# EFM32GG980F1024 register map
File version: 5.8.2
CPU: CM3 r2p1, little endian, MPU, no FPU, 3 interrupt priority bits
Registers are 32-bit, read-write, reset 0x0 unless marked. A register's access mark holds for its fields unless they carry their own. Offsets are from the block's base; [hi:lo] are bit positions; {n}, {i} and the like mark numbered series.

## CMU
Base 0x400C8000
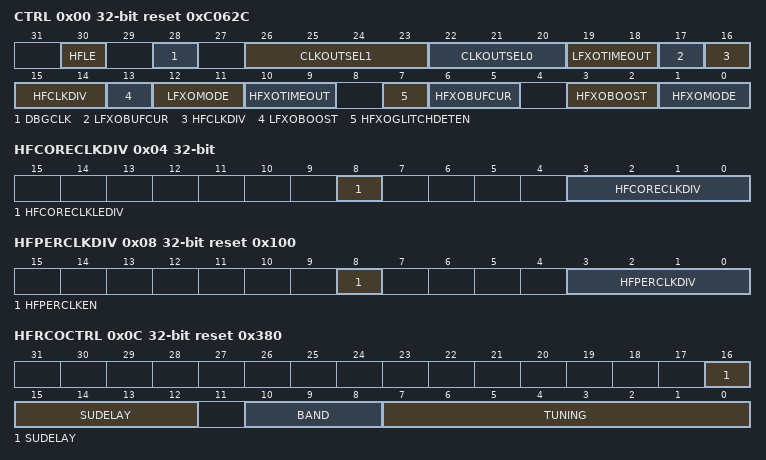
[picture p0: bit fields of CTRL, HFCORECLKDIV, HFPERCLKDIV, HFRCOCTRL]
0x00 CTRL reset 0xC062C — CMU Control Register
  [30] HFLE — High-Frequency LE Interface
  [28] DBGCLK — Debug Clock
  [26:23] CLKOUTSEL1 — Clock Output Select 1
    0=LFRCO (LFRCO (directly from oscillator).); 1=LFXO (LFXO (directly from oscillator).); 2=HFCLK (HFCLK (undivided).); 3=LFXOQ (LFXO (qualified).); 4=HFXOQ (HFXO (qualified).); 5=LFRCOQ (LFRCO (qualified).); 6=HFRCOQ (HFRCO (qualified).); 7=AUXHFRCOQ (AUXHFRCO (qualified).)
  [22:20] CLKOUTSEL0 — Clock Output Select 0
    0=HFRCO (HFRCO (directly from oscillator).); 1=HFXO (HFXO (directly from oscillator).); 2=HFCLK2; 3=HFCLK4; 4=HFCLK8; 5=HFCLK16; 6=ULFRCO (ULFRCO (directly from oscillator).); 7=AUXHFRCO (AUXHFRCO (directly from oscillator).)
  [19:18] LFXOTIMEOUT
    0=8CYCLES (Timeout period of 8 cycles.); 1=1KCYCLES (Timeout period of 1024 cycles.); 2=16KCYCLES (Timeout period of 16384 cycles.); 3=32KCYCLES (Timeout period of 32768 cycles.)
  [17] LFXOBUFCUR — LFXO Boost Buffer Current
  [16:14] HFCLKDIV — HFCLK Division
  [13] LFXOBOOST — LFXO Start-up Boost Current
  [12:11] LFXOMODE
    0=XTAL (32.768 kHz crystal oscillator.); 1=BUFEXTCLK (An AC coupled buffer is coupled in series with LFXTAL_N pin, suitable for external sinus wave (32.768 kHz).); 2=DIGEXTCLK (Digital external clock on LFXTAL_N pin. Oscillator is effectively bypassed.)
  [10:9] HFXOTIMEOUT
    0=8CYCLES (Timeout period of 8 cycles.); 1=256CYCLES (Timeout period of 256 cycles.); 2=1KCYCLES (Timeout period of 1024 cycles.); 3=16KCYCLES (Timeout period of 16384 cycles.)
  [7] HFXOGLITCHDETEN — HFXO Glitch Detector Enable
  [6:5] HFXOBUFCUR — HFXO Boost Buffer Current
    1=BOOSTUPTO32MHZ (Boost Buffer Current level when HFXO is below or equal to 32 MHz.); 3=BOOSTABOVE32MHZ (Boost Buffer Current Level when HFXO is above 32 MHz.)
  [3:2] HFXOBOOST — HFXO Start-up Boost Current
    0=50PCENT; 1=70PCENT; 2=80PCENT; 3=100PCENT (100 % (default).)
  [1:0] HFXOMODE
    0=XTAL (4-48 MHz crystal oscillator.); 1=BUFEXTCLK (An AC coupled buffer is coupled in series with HFXTAL_N, suitable for external sine wave (4-48 MHz). The sine wave should have a minimum of 200 mV peak to peak.); 2=DIGEXTCLK (Digital external clock on HFXTAL_N pin. Oscillator is effectively bypassed.)
0x04 HFCORECLKDIV — High Frequency Core Clock Division Register
  [8] HFCORECLKLEDIV — Additional Division Factor For HFCORECLKLE
  [3:0] HFCORECLKDIV — HFCORECLK Divider
    0=HFCLK (HFCORECLK = HFCLK.); 1=HFCLK2 (HFCORECLK = HFCLK/2.); 2=HFCLK4 (HFCORECLK = HFCLK/4.); 3=HFCLK8 (HFCORECLK = HFCLK/8.); 4=HFCLK16 (HFCORECLK = HFCLK/16.); 5=HFCLK32 (HFCORECLK = HFCLK/32.); 6=HFCLK64 (HFCORECLK = HFCLK/64.); 7=HFCLK128 (HFCORECLK = HFCLK/128.); 8=HFCLK256 (HFCORECLK = HFCLK/256.); 9=HFCLK512 (HFCORECLK = HFCLK/512.)
0x08 HFPERCLKDIV reset 0x100 — High Frequency Peripheral Clock Division Register
  [8] HFPERCLKEN — HFPERCLK Enable
  [3:0] HFPERCLKDIV — HFPERCLK Divider
    0=HFCLK (HFPERCLK = HFCLK.); 1=HFCLK2 (HFPERCLK = HFCLK/2.); 2=HFCLK4 (HFPERCLK = HFCLK/4.); 3=HFCLK8 (HFPERCLK = HFCLK/8.); 4=HFCLK16 (HFPERCLK = HFCLK/16.); 5=HFCLK32 (HFPERCLK = HFCLK/32.); 6=HFCLK64 (HFPERCLK = HFCLK/64.); 7=HFCLK128 (HFPERCLK = HFCLK/128.); 8=HFCLK256 (HFPERCLK = HFCLK/256.); 9=HFCLK512 (HFPERCLK = HFCLK/512.)
0x0C HFRCOCTRL reset 0x380 — HFRCO Control Register
  [16:12] SUDELAY — HFRCO Start-up Delay
  [10:8] BAND — HFRCO Band Select
    0=1MHZ (1 MHz band. NOTE: Also set the TUNING value (bits 7:0) when changing band.); 1=7MHZ (7 MHz band. NOTE: Also set the TUNING value (bits 7:0) when changing band.); 2=11MHZ (11 MHz band. NOTE: Also set the TUNING value (bits 7:0) when changing band.); 3=14MHZ (14 MHz band. NOTE: Also set the TUNING value (bits 7:0) when changing band.); 4=21MHZ (21 MHz band. NOTE: Also set the TUNING value (bits 7:0) when changing band.); 5=28MHZ (28 MHz band. NOTE: Also set the TUNING value (bits 7:0) when changing band.)
  [7:0] TUNING — HFRCO Tuning Value
0x10 LFRCOCTRL reset 0x40 — LFRCO Control Register
  [6:0] TUNING — LFRCO Tuning Value
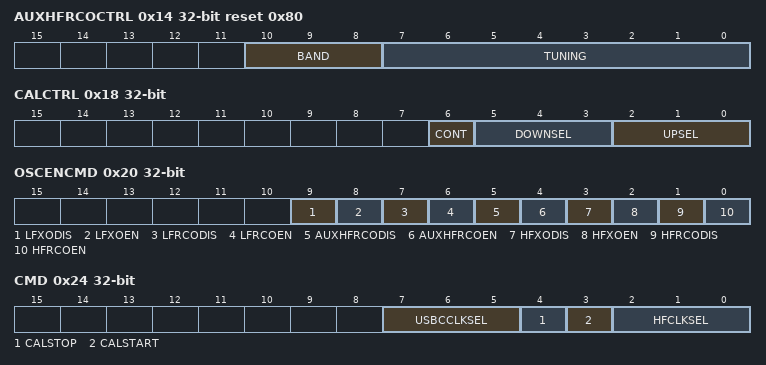
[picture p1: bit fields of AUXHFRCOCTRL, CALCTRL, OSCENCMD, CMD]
0x14 AUXHFRCOCTRL reset 0x80 — AUXHFRCO Control Register
  [10:8] BAND — AUXHFRCO Band Select
    0=14MHZ (14 MHz band. NOTE: Also set the TUNING value (bits 7:0) when changing band.); 1=11MHZ (11 MHz band. NOTE: Also set the TUNING value (bits 7:0) when changing band.); 2=7MHZ (7 MHz band. NOTE: Also set the TUNING value (bits 7:0) when changing band.); 3=1MHZ (1 MHz band. NOTE: Also set the TUNING value (bits 7:0) when changing band.); 6=28MHZ (28 MHz band. NOTE: Also set the TUNING value (bits 7:0) when changing band.); 7=21MHZ (21 MHz band. NOTE: Also set the TUNING value (bits 7:0) when changing band.)
  [7:0] TUNING — AUXHFRCO Tuning Value
0x18 CALCTRL — Calibration Control Register
  [6] CONT — Continuous Calibration
  [5:3] DOWNSEL — Calibration Down-counter Select
    0=HFCLK (Select HFCLK for down-counter.); 1=HFXO (Select HFXO for down-counter.); 2=LFXO (Select LFXO for down-counter.); 3=HFRCO (Select HFRCO for down-counter.); 4=LFRCO (Select LFRCO for down-counter.); 5=AUXHFRCO (Select AUXHFRCO for down-counter.)
  [2:0] UPSEL — Calibration Up-counter Select
    0=HFXO (Select HFXO as up-counter.); 1=LFXO (Select LFXO as up-counter.); 2=HFRCO (Select HFRCO as up-counter.); 3=LFRCO (Select LFRCO as up-counter.); 4=AUXHFRCO (Select AUXHFRCO as up-counter.)
0x1C CALCNT — Calibration Counter Register
  [19:0] CALCNT — Calibration Counter
0x20 OSCENCMD wo — Oscillator Enable/Disable Command Register
  [9] LFXODIS — LFXO Disable
  [8] LFXOEN — LFXO Enable
  [7] LFRCODIS — LFRCO Disable
  [6] LFRCOEN — LFRCO Enable
  [5] AUXHFRCODIS — AUXHFRCO Disable
  [4] AUXHFRCOEN — AUXHFRCO Enable
  [3] HFXODIS — HFXO Disable
  [2] HFXOEN — HFXO Enable
  [1] HFRCODIS — HFRCO Disable
  [0] HFRCOEN — HFRCO Enable
0x24 CMD wo — Command Register
  [7:5] USBCCLKSEL — USB Core Clock Select
    1=HFCLKNODIV (Select HFCLK (undivided) as HFCORECLKUSBC.); 2=LFXO (Select LFXO as HFCORECLKUSBC.); 3=LFRCO (Select LFRCO as HFCORECLKUSBC.)
  [4] CALSTOP — Calibration Stop
  [3] CALSTART — Calibration Start
  [2:0] HFCLKSEL — HFCLK Select
    1=HFRCO (Select HFRCO as HFCLK.); 2=HFXO (Select HFXO as HFCLK.); 3=LFRCO (Select LFRCO as HFCLK.); 4=LFXO (Select LFXO as HFCLK.)
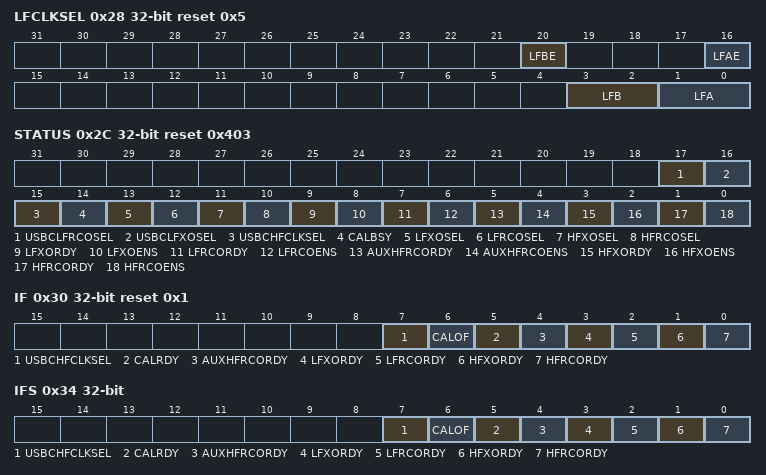
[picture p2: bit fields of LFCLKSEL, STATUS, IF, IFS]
0x28 LFCLKSEL reset 0x5 — Low Frequency Clock Select Register
  [20] LFBE — Clock Select for LFB Extended
  [16] LFAE — Clock Select for LFA Extended
  [3:2] LFB — Clock Select for LFB
    0=DISABLED (LFBCLK is disabled); 1=LFRCO (LFRCO selected as LFBCLK); 2=LFXO (LFXO selected as LFBCLK); 3=HFCORECLKLEDIV2 (HFCORECLKLE divided by two or four is selected as LFACLK. The division factor is determined by CMU_CTRL_HFLE and CMU_HFCORECLKDIV_HFCORECLKLEDIV.)
  [1:0] LFA — Clock Select for LFA
    0=DISABLED (LFACLK is disabled); 1=LFRCO (LFRCO selected as LFACLK); 2=LFXO (LFXO selected as LFACLK); 3=HFCORECLKLEDIV2 (HFCORECLKLE divided by two or four is selected as LFACLK. The division factor is determined by CMU_CTRL_HFLE and CMU_HFCORECLKDIV_HFCORECLKLEDIV.)
0x2C STATUS ro reset 0x403
  [17] USBCLFRCOSEL — USBC LFRCO Selected
  [16] USBCLFXOSEL — USBC LFXO Selected
  [15] USBCHFCLKSEL — USBC HFCLK Selected
  [14] CALBSY — Calibration Busy
  [13] LFXOSEL — LFXO Selected
  [12] LFRCOSEL — LFRCO Selected
  [11] HFXOSEL — HFXO Selected
  [10] HFRCOSEL — HFRCO Selected
  [9] LFXORDY — LFXO Ready
  [8] LFXOENS — LFXO Enable Status
  [7] LFRCORDY — LFRCO Ready
  [6] LFRCOENS — LFRCO Enable Status
  [5] AUXHFRCORDY — AUXHFRCO Ready
  [4] AUXHFRCOENS — AUXHFRCO Enable Status
  [3] HFXORDY — HFXO Ready
  [2] HFXOENS — HFXO Enable Status
  [1] HFRCORDY — HFRCO Ready
  [0] HFRCOENS — HFRCO Enable Status
0x30 IF ro reset 0x1 — Interrupt Flag Register
  [7] USBCHFCLKSEL — USBC HFCLK Selected Interrupt Flag
  [6] CALOF — Calibration Overflow Interrupt Flag
  [5] CALRDY — Calibration Ready Interrupt Flag
  [4] AUXHFRCORDY — AUXHFRCO Ready Interrupt Flag
  [3] LFXORDY — LFXO Ready Interrupt Flag
  [2] LFRCORDY — LFRCO Ready Interrupt Flag
  [1] HFXORDY — HFXO Ready Interrupt Flag
  [0] HFRCORDY — HFRCO Ready Interrupt Flag
0x34 IFS wo — Interrupt Flag Set Register
  [7] USBCHFCLKSEL — USBC HFCLK Selected Interrupt Flag Set
  [6] CALOF — Calibration Overflow Interrupt Flag Set
  [5] CALRDY — Calibration Ready Interrupt Flag Set
  [4] AUXHFRCORDY — AUXHFRCO Ready Interrupt Flag Set
  [3] LFXORDY — LFXO Ready Interrupt Flag Set
  [2] LFRCORDY — LFRCO Ready Interrupt Flag Set
  [1] HFXORDY — HFXO Ready Interrupt Flag Set
  [0] HFRCORDY — HFRCO Ready Interrupt Flag Set
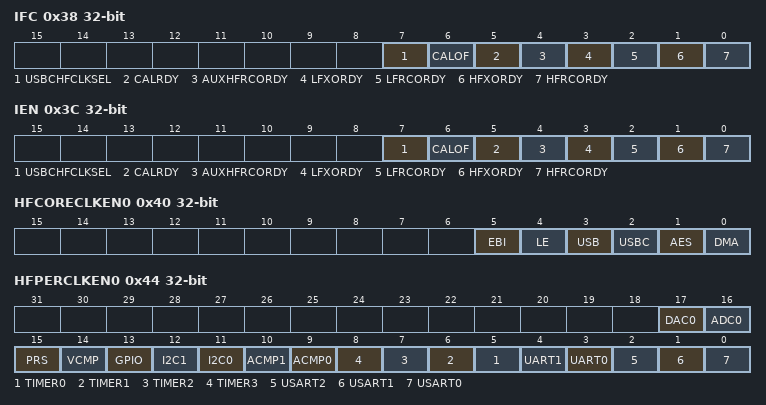
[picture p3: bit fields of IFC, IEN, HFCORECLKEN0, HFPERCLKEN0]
0x38 IFC wo — Interrupt Flag Clear Register
  [7] USBCHFCLKSEL — USBC HFCLK Selected Interrupt Flag Clear
  [6] CALOF — Calibration Overflow Interrupt Flag Clear
  [5] CALRDY — Calibration Ready Interrupt Flag Clear
  [4] AUXHFRCORDY — AUXHFRCO Ready Interrupt Flag Clear
  [3] LFXORDY — LFXO Ready Interrupt Flag Clear
  [2] LFRCORDY — LFRCO Ready Interrupt Flag Clear
  [1] HFXORDY — HFXO Ready Interrupt Flag Clear
  [0] HFRCORDY — HFRCO Ready Interrupt Flag Clear
0x3C IEN — Interrupt Enable Register
  [7] USBCHFCLKSEL — USBC HFCLK Selected Interrupt Enable
  [6] CALOF — Calibration Overflow Interrupt Enable
  [5] CALRDY — Calibration Ready Interrupt Enable
  [4] AUXHFRCORDY — AUXHFRCO Ready Interrupt Enable
  [3] LFXORDY — LFXO Ready Interrupt Enable
  [2] LFRCORDY — LFRCO Ready Interrupt Enable
  [1] HFXORDY — HFXO Ready Interrupt Enable
  [0] HFRCORDY — HFRCO Ready Interrupt Enable
0x40 HFCORECLKEN0 — High Frequency Core Clock Enable Register 0
  [5] EBI — External Bus Interface Clock Enable
  [4] LE — Low Energy Peripheral Interface Clock Enable
  [3] USB — Universal Serial Bus Interface Clock Enable
  [2] USBC — Universal Serial Bus Interface Core Clock Enable
  [1] AES — Advanced Encryption Standard Accelerator Clock Enable
  [0] DMA — Direct Memory Access Controller Clock Enable
0x44 HFPERCLKEN0 — High Frequency Peripheral Clock Enable Register 0
  [17] DAC0 — Digital to Analog Converter 0 Clock Enable
  [16] ADC0 — Analog to Digital Converter 0 Clock Enable
  [15] PRS — Peripheral Reflex System Clock Enable
  [14] VCMP — Voltage Comparator Clock Enable
  [13] GPIO — General purpose Input/Output Clock Enable
  [12] I2C1 — I2C 1 Clock Enable
  [11] I2C0 — I2C 0 Clock Enable
  [10] ACMP1 — Analog Comparator 1 Clock Enable
  [9] ACMP0 — Analog Comparator 0 Clock Enable
  [n+5] TIMER{n} (n=0..3) — Timer {n} Clock Enable
  [4] UART1 — Universal Asynchronous Receiver/Transmitter 1 Clock Enable
  [3] UART0 — Universal Asynchronous Receiver/Transmitter 0 Clock Enable
  [2] USART2 — Universal Synchronous/Asynchronous Receiver/Transmitter 2 Clock Enable
  [1] USART1 — Universal Synchronous/Asynchronous Receiver/Transmitter 1 Clock Enable
  [0] USART0 — Universal Synchronous/Asynchronous Receiver/Transmitter 0 Clock Enable
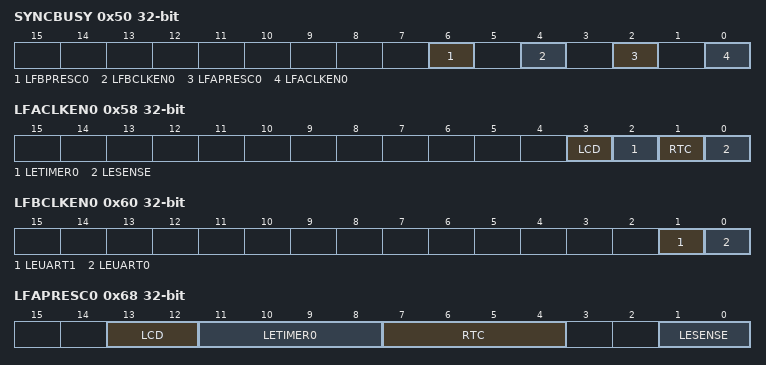
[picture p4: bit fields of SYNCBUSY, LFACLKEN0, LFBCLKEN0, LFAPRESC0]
0x50 SYNCBUSY ro — Synchronization Busy Register
  [6] LFBPRESC0 — Low Frequency B Prescaler 0 Busy
  [4] LFBCLKEN0 — Low Frequency B Clock Enable 0 Busy
  [2] LFAPRESC0 — Low Frequency A Prescaler 0 Busy
  [0] LFACLKEN0 — Low Frequency A Clock Enable 0 Busy
0x54 FREEZE
  [0] REGFREEZE — Register Update Freeze
0x58 LFACLKEN0 — Low Frequency A Clock Enable Register 0 (Async Reg)
  [3] LCD — Liquid Crystal Display Controller Clock Enable
  [2] LETIMER0 — Low Energy Timer 0 Clock Enable
  [1] RTC — Real-Time Counter Clock Enable
  [0] LESENSE — Low Energy Sensor Interface Clock Enable
0x60 LFBCLKEN0 — Low Frequency B Clock Enable Register 0 (Async Reg)
  [1] LEUART1 — Low Energy UART 1 Clock Enable
  [0] LEUART0 — Low Energy UART 0 Clock Enable
0x68 LFAPRESC0 — Low Frequency A Prescaler Register 0 (Async Reg)
  [13:12] LCD — Liquid Crystal Display Controller Prescaler
    0=DIV16 (LFACLKLCD = LFACLK/16); 1=DIV32 (LFACLKLCD = LFACLK/32); 2=DIV64 (LFACLKLCD = LFACLK/64); 3=DIV128 (LFACLKLCD = LFACLK/128)
  [11:8] LETIMER0 — Low Energy Timer 0 Prescaler
    0=DIV1 (LFACLKLETIMER0 = LFACLK); 1=DIV2 (LFACLKLETIMER0 = LFACLK/2); 2=DIV4 (LFACLKLETIMER0 = LFACLK/4); 3=DIV8 (LFACLKLETIMER0 = LFACLK/8); 4=DIV16 (LFACLKLETIMER0 = LFACLK/16); 5=DIV32 (LFACLKLETIMER0 = LFACLK/32); 6=DIV64 (LFACLKLETIMER0 = LFACLK/64); 7=DIV128 (LFACLKLETIMER0 = LFACLK/128); 8=DIV256 (LFACLKLETIMER0 = LFACLK/256); 9=DIV512 (LFACLKLETIMER0 = LFACLK/512); 10=DIV1024 (LFACLKLETIMER0 = LFACLK/1024); 11=DIV2048 (LFACLKLETIMER0 = LFACLK/2048); 12=DIV4096 (LFACLKLETIMER0 = LFACLK/4096); 13=DIV8192 (LFACLKLETIMER0 = LFACLK/8192); 14=DIV16384 (LFACLKLETIMER0 = LFACLK/16384); 15=DIV32768 (LFACLKLETIMER0 = LFACLK/32768)
  [7:4] RTC — Real-Time Counter Prescaler
    0=DIV1 (LFACLKRTC = LFACLK); 1=DIV2 (LFACLKRTC = LFACLK/2); 2=DIV4 (LFACLKRTC = LFACLK/4); 3=DIV8 (LFACLKRTC = LFACLK/8); 4=DIV16 (LFACLKRTC = LFACLK/16); 5=DIV32 (LFACLKRTC = LFACLK/32); 6=DIV64 (LFACLKRTC = LFACLK/64); 7=DIV128 (LFACLKRTC = LFACLK/128); 8=DIV256 (LFACLKRTC = LFACLK/256); 9=DIV512 (LFACLKRTC = LFACLK/512); 10=DIV1024 (LFACLKRTC = LFACLK/1024); 11=DIV2048 (LFACLKRTC = LFACLK/2048); 12=DIV4096 (LFACLKRTC = LFACLK/4096); 13=DIV8192 (LFACLKRTC = LFACLK/8192); 14=DIV16384 (LFACLKRTC = LFACLK/16384); 15=DIV32768 (LFACLKRTC = LFACLK/32768)
  [1:0] LESENSE — Low Energy Sensor Interface Prescaler
    0=DIV1 (LFACLKLESENSE = LFACLK); 1=DIV2 (LFACLKLESENSE = LFACLK/2); 2=DIV4 (LFACLKLESENSE = LFACLK/4); 3=DIV8 (LFACLKLESENSE = LFACLK/8)
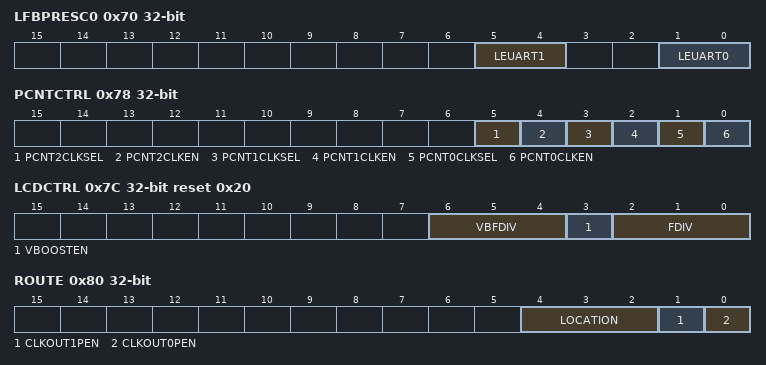
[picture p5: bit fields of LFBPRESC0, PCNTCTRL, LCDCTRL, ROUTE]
0x70 LFBPRESC0 — Low Frequency B Prescaler Register 0 (Async Reg)
  [5:4] LEUART1 — Low Energy UART 1 Prescaler
    0=DIV1 (LFBCLKLEUART1 = LFBCLK); 1=DIV2 (LFBCLKLEUART1 = LFBCLK/2); 2=DIV4 (LFBCLKLEUART1 = LFBCLK/4); 3=DIV8 (LFBCLKLEUART1 = LFBCLK/8)
  [1:0] LEUART0 — Low Energy UART 0 Prescaler
    0=DIV1 (LFBCLKLEUART0 = LFBCLK); 1=DIV2 (LFBCLKLEUART0 = LFBCLK/2); 2=DIV4 (LFBCLKLEUART0 = LFBCLK/4); 3=DIV8 (LFBCLKLEUART0 = LFBCLK/8)
0x78 PCNTCTRL — PCNT Control Register
  [5] PCNT2CLKSEL — PCNT2 Clock Select
  [4] PCNT2CLKEN — PCNT2 Clock Enable
  [3] PCNT1CLKSEL — PCNT1 Clock Select
  [2] PCNT1CLKEN — PCNT1 Clock Enable
  [1] PCNT0CLKSEL — PCNT0 Clock Select
  [0] PCNT0CLKEN — PCNT0 Clock Enable
0x7C LCDCTRL reset 0x20 — LCD Control Register
  [6:4] VBFDIV — Voltage Boost Frequency Division
    0=DIV1 (Voltage Boost update Frequency = LFACLK.); 1=DIV2 (Voltage Boost update Frequency = LFACLK/2.); 2=DIV4 (Voltage Boost update Frequency = LFACLK/4.); 3=DIV8 (Voltage Boost update Frequency = LFACLK/8.); 4=DIV16 (Voltage Boost update Frequency = LFACLK/16.); 5=DIV32 (Voltage Boost update Frequency = LFACLK/32.); 6=DIV64 (Voltage Boost update Frequency = LFACLK/64.); 7=DIV128 (Voltage Boost update Frequency = LFACLK/128.)
  [3] VBOOSTEN — Voltage Boost Enable
  [2:0] FDIV — Frame Rate Control
0x80 ROUTE — I/O Routing Register
  [4:2] LOCATION — I/O Location
    0=LOC0 (Location 0); 1=LOC1 (Location 1); 2=LOC2 (Location 2)
  [1] CLKOUT1PEN — CLKOUT1 Pin Enable
  [0] CLKOUT0PEN — CLKOUT0 Pin Enable
0x84 LOCK — Configuration Lock Register
  [15:0] LOCKKEY — Configuration Lock Key
    0=UNLOCKED; 1=LOCKED

## Notices in the file
# License
Copyright 2019 Silicon Laboratories Inc. www.silabs.com
SPDX-License-Identifier: Zlib
The licensor of this software is Silicon Laboratories Inc.
This software is provided 'as-is', without any express or implied
warranty. In no event will the authors be held liable for any damages
arising from the use of this software.
Permission is granted to anyone to use this software for any purpose,
including commercial applications, and to alter it and redistribute it
freely, subject to the following restrictions:
1. The origin of this software must not be misrepresented; you must not
claim that you wrote the original software. If you use this software
in a product, an acknowledgment in the product documentation would be
appreciated but is not required.
2. Altered source versions must be plainly marked as such, and must not be
misrepresented as being the original software.
3. This notice may not be removed or altered from any source distribution.
